# STM32WBA62 register map
File version: 1.1
CPU: CM33 r0p1, little endian, MPU, FPU, 4 interrupt priority bits
Registers are 32-bit, read-write, reset 0x0 unless marked. A register's access mark holds for its fields unless they carry their own. Offsets are from the block's base; [hi:lo] are bit positions; 'fields as' and 'values as' point back to an identical list.

## RCC — RCC address block description
Base 0x46020C00
Same registers: SEC_RCC 0x56020C00
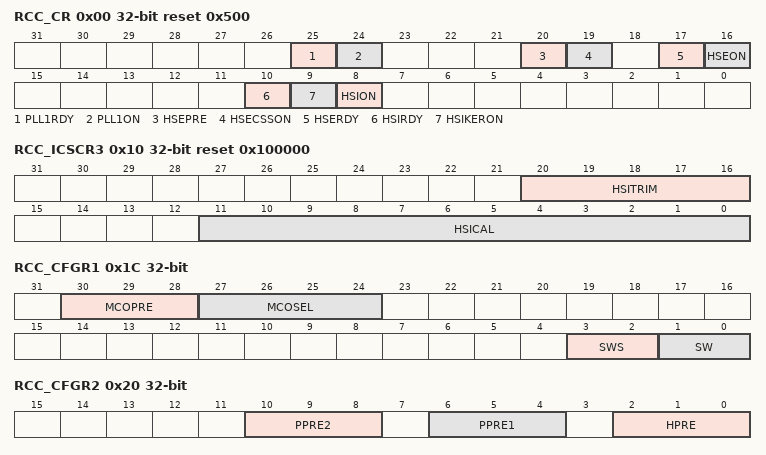
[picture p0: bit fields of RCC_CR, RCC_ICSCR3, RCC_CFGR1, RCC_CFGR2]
0x00 RCC_CR reset 0x500 — RCC clock control register
  [25] PLL1RDY ro — PLL1 clock ready flag
    0=PLL1 unlocked; 1=PLL1 locked (PLL1RDY remains set when PLL1 is selected as sysclk and PLL1 is disabled by HSECSS failure)
  [24] PLL1ON — PLL1 enable
    0=PLL1 off; 1=PLL1 on
  [20] HSEPRE — HSE32 clock for SYSCLK prescaler
    0=HSE32 not divided, SYSCLK = HSE32; 1=HSE32 divided, SYSCLK = HSE32/2
  [19] HSECSSON — HSE32 clock security system enable
    0=HSE32 clock security system off (clock detector off); 1=HSE32 clock security system on (clock detector on if the HSE32 oscillator is stable, off if not)
  [17] HSERDY ro — HSE32 clock ready flag
    0=HSE32 oscillator not ready; 1=HSE32 oscillator ready to be used by the CPU
  [16] HSEON — HSE32 clock enable
    0=HSE32 oscillator not requested by the CPU; 1=HSE32 oscillator ON
  [10] HSIRDY ro — HSI16 clock ready flag
    0=HSI16 oscillator not ready; 1=HSI16 oscillator ready
  [9] HSIKERON — HSI16 enable for some peripheral kernels
    0=No effect on HSI16 oscillator; 1=HSI16 oscillator forced on even in Stop mode
  [8] HSION — HSI16 clock enable
    0=HSI16 oscillator off; 1=HSI16 oscillator on
0x10 RCC_ICSCR3 reset 0x100000 (reset mask 0xFFFFF000) — RCC internal clock sources calibration register 3
  [20:16] HSITRIM — HSI16 clock trimming
  [11:0] HSICAL ro — HSI16 clock calibration
0x1C RCC_CFGR1 — RCC clock configuration register 1
  [30:28] MCOPRE — microcontroller clock output prescaler
    0=MCO divided by 1; 1=MCO divided by 2; 2=MCO divided by 4; 3=MCO divided by 8; 4=MCO divided by 16
  [27:24] MCOSEL — microcontroller clock output
    0=MCO output disabled, no clock on MCO; 1=sysclkpre system clock after PLL1RCLKPRE division selected; 3=HSI16 clock selected; 4=HSE32 clock selected; 5=pll1rclk clock selected; 6=LSI clock selected; 7=LSE clock selected; 8=pll1pclk clock selected; 9=pll1qclk clock selected; 10=hclk5 clock selected
  [3:2] SWS ro — system clock switch status
    0=HSI16 oscillator used as system clock; 2=HSE32 or HSE32/2, as defined by HSEPRE, used as system clock; 3=pll1rclk used as system clock
  [1:0] SW — system clock switch
    0=HSI16 selected as system clock; 2=HSE32 or HSE32/2, as defined by HSEPRE, selected as system clock; 3=pll1rclk selected as system clock
0x20 RCC_CFGR2 — RCC clock configuration register 2
  [10:8] PPRE2 — APB2 prescaler
    4=pclk2 = hclk1 divided by 2; 5=pclk2 = hclk1 divided by 4; 6=pclk2 = hclk1 divided by 8; 7=pclk2 = hclk1 divided by 16
  [6:4] PPRE1 — APB1 prescaler
    4=pclk1 = hclk1 divided by 2; 5=pclk1 = hclk1 divided by 4; 6=pclk1 = hclk1 divided by 8; 7=pclk1 = hclk1 divided by 16
  [2:0] HPRE — AHB1, AHB2 and AHB4 prescaler
    4=hclk1 = SYSCLK divided by 2; 5=hclk1 = SYSCLK divided by 4; 6=hclk1 = SYSCLK divided by 8; 7=hclk1 = SYSCLK divided by 16
0x24 RCC_CFGR3 — RCC clock configuration register 3
  [6:4] PPRE7 — APB7 prescaler
    4=hclk1 divided by 2; 5=hclk1 divided by 4; 6=hclk1 divided by 8; 7=hclk1 divided by 16
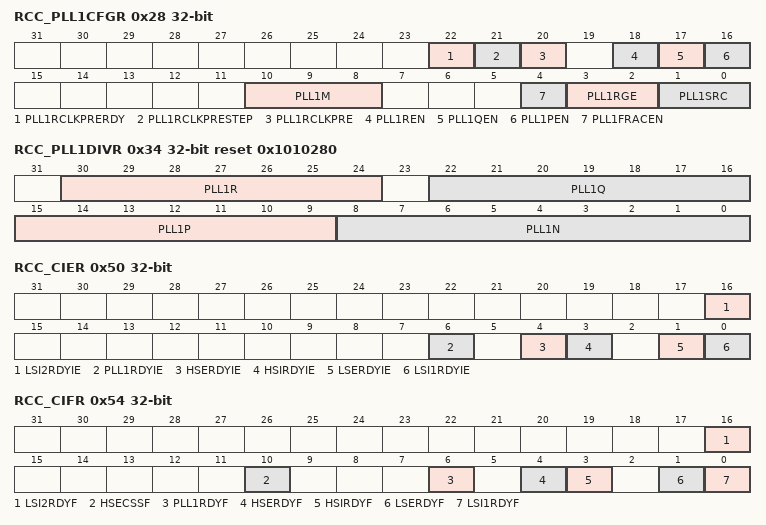
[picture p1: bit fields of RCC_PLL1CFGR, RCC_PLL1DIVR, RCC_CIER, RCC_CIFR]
0x28 RCC_PLL1CFGR — RCC PLL1 configuration register
  [22] PLL1RCLKPRERDY ro — pll1rclkpre not divided ready.
    0=pll1rclk divided; 1=pll1rclk not divided ready
  [21] PLL1RCLKPRESTEP — pll1rclk clock for SYSCLK prescaler division step selection
    0=pll1rclk 2-step division; 1=pll1rclk 3-step division
  [20] PLL1RCLKPRE — pll1rclk clock for SYSCLK prescaler division enable
    0=pll1rclk not divided, sysclkpre = pll1rclk; 1=pll1rclk divided, sysclkpre = pll1rclk divided
  [18] PLL1REN — PLL1 DIVR divider output enable
    0=pll1rclk output disabled; 1=pll1rclk output enabled
  [17] PLL1QEN — PLL1 DIVQ divider output enable
    0=pll1qclk output disabled; 1=pll1qclk output enabled
  [16] PLL1PEN — PLL1 DIVP divider output enable
    0=pll1pclk output disabled; 1=pll1pclk output enabled
  [10:8] PLL1M — Prescaler for PLL1
    0=division by 1 (bypass); 1=division by 2; 2=division by 3; 7=division by 8
  [4] PLL1FRACEN — PLL1 fractional latch enable
  [3:2] PLL1RGE — PLL1 input frequency range
    3=PLL1 input (ref_ck) clock range frequency between 8 and 16 MHz
  [1:0] PLL1SRC — PLL1 entry clock source
    0=no clock sent to PLL1; 2=HSI16 clock selected as PLL1 clock entry; 3=HSE32 clock after HSEPRE divider selected as PLL1 clock entry
0x34 RCC_PLL1DIVR reset 0x1010280 — RCC PLL1 dividers register
  [30:24] PLL1R — PLL1 DIVR division factor
    0=pll1rclk = VCO output frequency; 1=pll1rclk = VCO output frequency / 2 (default after reset); 2=pll1rclk = VCO output frequency / 3; 3=pll1rclk = VCO output frequency / 4; 127=pll1rclk = VCO output frequency / 128
  [22:16] PLL1Q — PLL1 DIVQ division factor
    0=pll1qclk = VCO output frequency; 1=pll1qclk = VCO output frequency / 2 (default after reset); 2=pll1qclk = VCO output frequency / 3; 3=pll1qclk = VCO output frequency / 4; 127=pll1qclk = VCO output frequency / 128
  [15:9] PLL1P — PLL1 DIVP division factor
    0=pll1pclk = VCO output frequency; 1=pll1pclk = VCO output frequency / 2 (default after reset); 2=pll1pclk = VCO output frequency; 3=pll1pclk = VCO output frequency / 4; 127=pll1pclk = VCO output frequency / 128
  [8:0] PLL1N — Multiplication factor for PLL1 VCO
    3=multiplication factor for PLL1 VCO = 4; 4=multiplication factor for PLL1 VCO = 5; 5=multiplication factor for PLL1 VCO = 6; 128=multiplication factor for PLL1 VCO = 129 (default after reset); 0x1FF=multiplication factor for PLL1 VCO = 512
0x38 RCC_PLL1FRACR — RCC PLL1 fractional divider register
  [15:3] PLL1FRACN — Fractional part of the multiplication factor for PLL1 VCO
0x50 RCC_CIER — RCC clock interrupt enable register
  [16] LSI2RDYIE — LSI2 ready interrupt enable
    0=LSI2 ready interrupt disabled; 1=LSI2 ready interrupt enabled
  [6] PLL1RDYIE — PLL1 ready interrupt enable
    0=PLL1 lock interrupt disabled; 1=PLL1 lock interrupt enabled
  [4] HSERDYIE — HSE32 ready interrupt enable
    0=HSE32 ready interrupt disabled; 1=HSE32 ready interrupt enabled
  [3] HSIRDYIE — HSI16 ready interrupt enable
    0=HSI16 ready interrupt disabled; 1=HSI16 ready interrupt enabled
  [1] LSERDYIE — LSE ready interrupt enable
    0=LSE ready interrupt disabled; 1=LSE ready interrupt enabled
  [0] LSI1RDYIE — LSI1 ready interrupt enable
    0=LSI1 ready interrupt disabled; 1=LSI1 ready interrupt enabled
0x54 RCC_CIFR ro — RCC clock interrupt flag register
  [16] LSI2RDYF — LSI2 ready interrupt flag
    0=no clock ready interrupt caused by the LSI2 oscillator; 1=clock ready interrupt caused by the LSI2 oscillator
  [10] HSECSSF — HSE32 clock security system interrupt flag
    0=no clock security interrupt caused by HSE32 clock failure; 1=clock security interrupt caused by HSE32 clock failure
  [6] PLL1RDYF — PLL1 ready interrupt flag
    0=no clock ready interrupt caused by PLL1 lock; 1=clock ready interrupt caused by PLL1 lock
  [4] HSERDYF — HSE32 ready interrupt flag
    0=no clock ready interrupt caused by the HSE32 oscillator; 1=clock ready interrupt caused by the HSE32 oscillator
  [3] HSIRDYF — HSI16 ready interrupt flag
    0=no clock ready interrupt caused by the HSI16 oscillator; 1=clock ready interrupt caused by the HSI16 oscillator
  [1] LSERDYF — LSE ready interrupt flag
    0=no clock ready interrupt caused by the LSE oscillator; 1=clock ready interrupt caused by the LSE oscillator
  [0] LSI1RDYF — LSI1 ready interrupt flag
    0=no clock ready interrupt caused by the LSI1 oscillator; 1=clock ready interrupt caused by the LSI1 oscillator
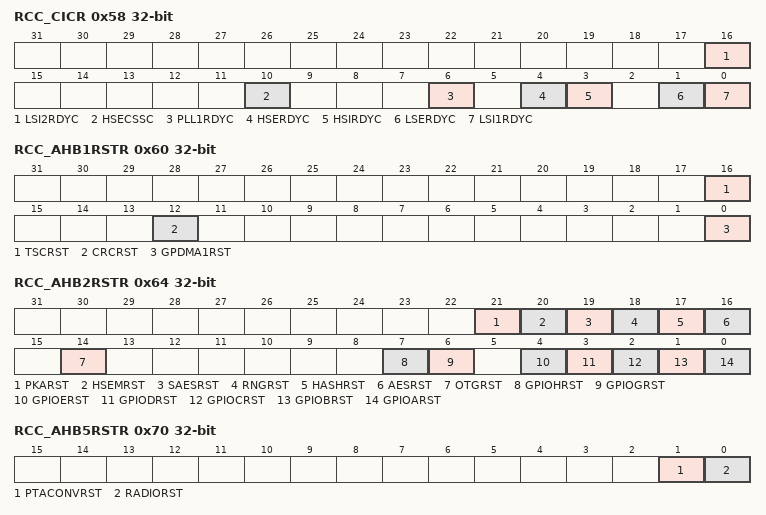
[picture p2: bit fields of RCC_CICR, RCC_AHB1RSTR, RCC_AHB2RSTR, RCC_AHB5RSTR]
0x58 RCC_CICR wo — RCC clock interrupt clear register
  [16] LSI2RDYC — LSI2 ready interrupt clear
  [10] HSECSSC — High speed external clock security system interrupt clear
  [6] PLL1RDYC — PLL1 ready interrupt clear
  [4] HSERDYC — HSE32 ready interrupt clear
  [3] HSIRDYC — HSI16 ready interrupt clear
  [1] LSERDYC — LSE ready interrupt clear
  [0] LSI1RDYC — LSI1 ready interrupt clear
0x60 RCC_AHB1RSTR — RCC AHB1 peripheral reset register
  [16] TSCRST — TSC reset
    0=No effect; 1=Reset TSC
  [12] CRCRST — CRC reset
    0=No effect; 1=Reset CRC
  [0] GPDMA1RST — GPDMA1 reset
    0=No effect; 1=Reset GPDMA1
0x64 RCC_AHB2RSTR — RCC AHB2 peripheral reset register
  [21] PKARST — PKA reset
    0=No effect; 1=Reset PKA
  [20] HSEMRST — HSEM reset
    0=No effect; 1=Reset HSEM
  [19] SAESRST — SAES hardware accelerator reset
    0=No effect; 1=Reset SAES
  [18] RNGRST — Random number generator reset
    0=No effect; 1=Reset RNG
  [17] HASHRST — Hash reset
    0=No effect; 1=Reset HASH
  [16] AESRST — AES hardware accelerator reset
    0=No effect; 1=Reset AES
  [14] OTGRST — USB OTG_HS reset
    0=No effect; 1=Reset USB OTG_HS and USB OTG_HS PHY
  [7] GPIOHRST — IO port H reset
    0=No effect; 1=Reset IO port H
  [6] GPIOGRST — IO port G reset
    0=No effect; 1=Reset IO port G
  [4] GPIOERST — IO port E reset
    0=No effect; 1=Reset IO port E
  [3] GPIODRST — IO port D reset
    0=No effect; 1=Reset IO port D
  [2] GPIOCRST — IO port C reset
    0=No effect; 1=Reset IO port C
  [1] GPIOBRST — IO port B reset
    0=No effect; 1=Reset IO port B
  [0] GPIOARST — IO port A reset
    0=No effect; 1=Reset IO port A
0x6C RCC_AHB4RSTR — RCC AHB4 peripheral reset register
  [5] ADC4RST — ADC4 reset
    0=No effect; 1=Reset ADC4 interface
0x70 RCC_AHB5RSTR — RCC AHB5 peripheral reset register
  [1] PTACONVRST — PTACONV reset
    0=No effect; 1=Reset PTACONV
  [0] RADIORST — 2.
    0=No effect; 1=Reset 2
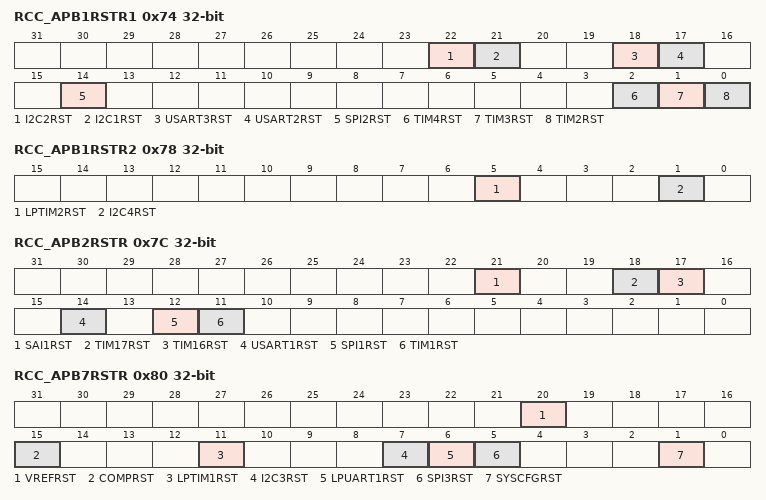
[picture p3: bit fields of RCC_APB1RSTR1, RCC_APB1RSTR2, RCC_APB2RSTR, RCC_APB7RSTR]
0x74 RCC_APB1RSTR1 — RCC APB1 peripheral reset register 1
  [22] I2C2RST — I2C2 reset
    0=No effect; 1=Reset I2C2
  [21] I2C1RST — I2C1 reset
    0=No effect; 1=Reset I2C1
  [18] USART3RST — USART3 reset
    0=No effect; 1=Reset USART3
  [17] USART2RST — USART2 reset
    0=No effect; 1=Reset USART2
  [14] SPI2RST — SPI2 reset
    0=No effect; 1=Reset SPI2
  [2] TIM4RST — TIM4 reset
    0=No effect; 1=Reset TIM4
  [1] TIM3RST — TIM3 reset
    0=No effect; 1=Reset TIM3
  [0] TIM2RST — TIM2 reset
    0=No effect; 1=Reset TIM2
0x78 RCC_APB1RSTR2 — RCC APB1 peripheral reset register 2
  [5] LPTIM2RST — LPTIM2 reset
    0=No effect; 1=Reset LPTIM2
  [1] I2C4RST — I2C4 reset
    0=No effect; 1=Reset I2C4
0x7C RCC_APB2RSTR — RCC APB2 peripheral reset register
  [21] SAI1RST — SAI1 reset
    0=No effect; 1=Reset SAI1
  [18] TIM17RST — TIM17 reset
    0=No effect; 1=Reset TIM17
  [17] TIM16RST — TIM16 reset
    0=No effect; 1=Reset TIM16
  [14] USART1RST — USART1 reset
    0=No effect; 1=Reset USART1
  [12] SPI1RST — SPI1 reset
    0=No effect; 1=Reset SPI1
  [11] TIM1RST — TIM1 reset
    0=No effect; 1=Reset TIM1
0x80 RCC_APB7RSTR — RCC APB7 peripheral reset register
  [20] VREFRST — VREFBUF reset
    0=No effect; 1=Reset VREFBUF
  [15] COMPRST — COMP reset
    0=No effect; 1=Reset COMP
  [11] LPTIM1RST — LPTIM1 reset
    0=No effect; 1=Reset LPTIM1
  [7] I2C3RST — I2C3 reset
    0=No effect; 1=Reset I2C3
  [6] LPUART1RST — LPUART1 reset
    0=No effect; 1=Reset LPUART1
  [5] SPI3RST — SPI3 reset
    0=No effect; 1=Reset SPI3
  [1] SYSCFGRST — SYSCFG reset
    0=No effect; 1=Reset SYSCFG
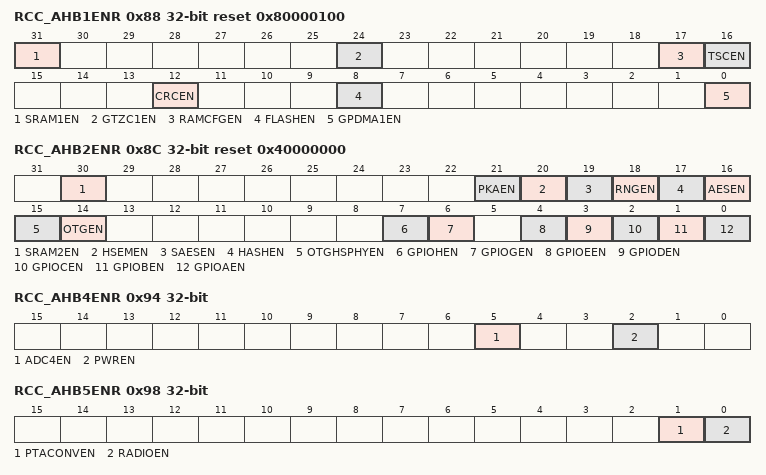
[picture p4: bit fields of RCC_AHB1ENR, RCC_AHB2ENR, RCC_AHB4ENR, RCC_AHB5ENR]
0x88 RCC_AHB1ENR reset 0x80000100 — RCC AHB1 peripheral clock enable register
  [31] SRAM1EN — SRAM1 bus clock enable
    0=SRAM1 bus clock disabled; 1=SRAM1 bus clock enabled
  [24] GTZC1EN — GTZC1 bus clock enable
    0=GTZC1 bus clock disabled; 1=GTZC1 bus clock enabled
  [17] RAMCFGEN — RAMCFG bus clock enable
    0=RAMCFG bus clock disabled; 1=RAMCFG bus clock enabled
  [16] TSCEN — Touch sensing controller bus clock enable
    0=TSC bus clock disabled; 1=TSC bus clock enabled
  [12] CRCEN — CRC bus clock enable
    0=CRC bus clock disabled; 1=CRC bus clock enabled
  [8] FLASHEN — FLASH bus clock enable
    0=FLASH bus clock disabled; 1=FLASH bus clock enabled
  [0] GPDMA1EN — GPDMA1 bus clock enable
    0=GPDMA1 bus clock disabled; 1=GPDMA1 bus clock enabled
0x8C RCC_AHB2ENR reset 0x40000000 — RCC AHB2 peripheral clock enable register
  [30] SRAM2EN — SRAM2 bus clock enable
    0=SRAM2 bus clock disabled; 1=SRAM2 bus clock enabled
  [21] PKAEN — PKA bus clock enable
    0=PKA bus clock disabled; 1=PKA bus clock enabled
  [20] HSEMEN — HSEM bus clock enable
    0=HSEM bus clock disabled; 1=HSEM bus clock enabled
  [19] SAESEN — SAES bus clock enable
    0=SAES bus clock disabled; 1=SAES bus clock enabled
  [18] RNGEN — RNG bus and kernel clocks enable
    0=RNG bus and kernel clocks disabled; 1=RNG bus and kernel clocks enabled
  [17] HASHEN — HASH bus clock enable
    0=HASH bus clock disabled; 1=HASH bus clock enabled
  [16] AESEN — AES bus clock enable
    0=AES bus clock disabled; 1=AES bus clock enabled
  [15] OTGHSPHYEN — USB OTG_HS PHY kernel clock enable
    0=USB OTG_HS PHY kernel clock disabled; 1=USB OTG_HS PHY kernel clock enabled
  [14] OTGEN — USB OTG_HS bus and kernel clock enable
    0=USB OTG_HS bus and kernel clock disabled; 1=USB OTG_HS bus and kernel clock enabled
  [7] GPIOHEN — IO port H bus clock enable
    0=IO port H bus clock disabled; 1=IO port H bus clock enabled
  [6] GPIOGEN — IO port G bus clock enable
    0=IO port G bus clock disabled; 1=IO port G bus clock enabled
  [4] GPIOEEN — IO port E bus clock enable
    0=IO port E bus clock disabled; 1=IO port E bus clock enabled
  [3] GPIODEN — IO port D bus clock enable
    0=IO port D bus clock disabled; 1=IO port D bus clock enabled
  [2] GPIOCEN — IO port C bus clock enable
    0=IO port C bus clock disabled; 1=IO port C bus clock enabled
  [1] GPIOBEN — IO port B bus clock enable
    0=IO port B bus clock disabled; 1=IO port B bus clock enabled
  [0] GPIOAEN — IO port A bus clock enable
    0=IO port A bus clock disabled; 1=IO port A bus clock enabled
0x94 RCC_AHB4ENR — RCC AHB4 peripheral clock enable register
  [5] ADC4EN — ADC4 bus and kernel clocks enable
    0=ADC4 bus and kernel clocks disabled; 1=ADC4 bus and kernel clocks enabled
  [2] PWREN — PWR bus clock enable
    0=PWR bus clock disabled; 1=PWR bus clock enabled
0x98 RCC_AHB5ENR — RCC AHB5 peripheral clock enable register
  [1] PTACONVEN — PTACONV bus clock enable
    0=PTACONV bus clock disabled; 1=PTACONV bus clock enabled
  [0] RADIOEN — 2.
    0=2; 1=2
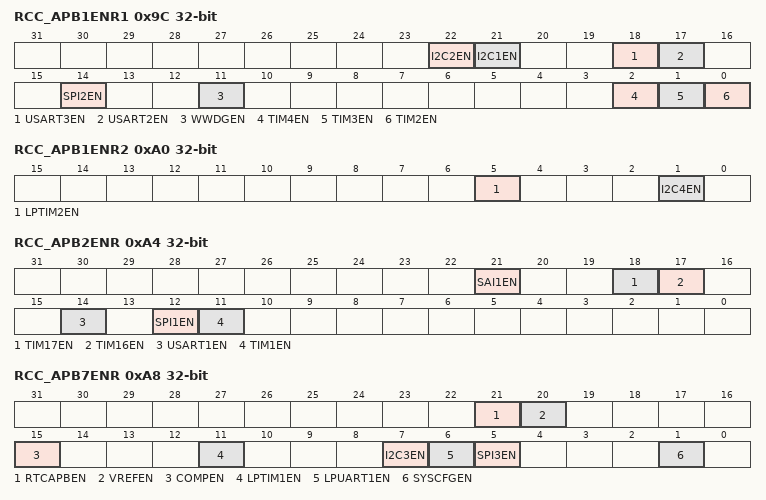
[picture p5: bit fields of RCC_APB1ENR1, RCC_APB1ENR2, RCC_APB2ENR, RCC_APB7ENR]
0x9C RCC_APB1ENR1 — RCC APB1 peripheral clock enable register 1
  [22] I2C2EN — I2C2 bus and kernel clocks enable
    0=I2C2 bus and kernel clocks disabled; 1=I2C2 bus and kernel clocks enabled
  [21] I2C1EN — I2C1 bus and kernel clocks enable
    0=I2C1 bus and kernel clocks disabled; 1=I2C1 bus and kernel clocks enabled
  [18] USART3EN — USART3 bus and kernel clocks enable
    0=USART3 bus and kernel clocks disabled; 1=USART3 bus and kernel clocks enabled
  [17] USART2EN — USART2 bus and kernel clocks enable
    0=USART2 bus and kernel clocks disabled; 1=USART2 bus and kernel clocks enabled
  [14] SPI2EN — SPI2 bus and kernel clocks enable
    0=SPI2 bus and kernel clocks disabled; 1=SPI2 bus and kernel clocks enabled
  [11] WWDGEN — WWDG bus clock enable
    0=WWDG bus clock disabled; 1=WWDG bus clock enabled
  [2] TIM4EN — TIM4 bus and kernel clocks enable
    0=TIM4 bus and kernel clocks disabled; 1=TIM4 bus and kernel clocks enabled
  [1] TIM3EN — TIM3 bus and kernel clocks enable
    0=TIM3 bus and kernel clocks disabled; 1=TIM3 bus and kernel clocks enabled
  [0] TIM2EN — TIM2 bus and kernel clocks enable
    0=TIM2 bus and kernel clocks disabled; 1=TIM2 bus and kernel clocks enabled
0xA0 RCC_APB1ENR2 — RCC APB1 peripheral clock enable register 2
  [5] LPTIM2EN — LPTIM2 bus and kernel clocks enable
    0=LPTIM2 bus and kernel clocks disabled; 1=LPTIM2 bus and kernel clocks enabled
  [1] I2C4EN — I2C4 bus and kernel clocks enable
    0=I2C4 bus and kernel clocks disabled; 1=I2C4 bus and kernel clocks enabled
0xA4 RCC_APB2ENR — RCC APB2 peripheral clock enable register
  [21] SAI1EN — SAI1 bus and kernel clocks enable
    0=SAI1 bus and kernel clocks disabled; 1=SAI1 bus and kernel clocks enabled
  [18] TIM17EN — TIM17 bus and kernel clocks enable
    0=TIM17 bus and kernel clocks disabled; 1=TIM17 bus and kernel clocks enabled
  [17] TIM16EN — TIM16 bus and kernel clocks enable
    0=TIM16 bus and kernel clocks disabled; 1=TIM16 bus and kernel clocks enabled
  [14] USART1EN — USART1bus and kernel clocks enable
    0=USART1 bus and kernel clocks disabled; 1=USART1 bus and kernel clocks enabled
  [12] SPI1EN — SPI1 bus and kernel clocks enable
    0=SPI1 bus and kernel clocks disabled; 1=SPI1 bus and kernel clocks enabled
  [11] TIM1EN — TIM1 bus and kernel clocks enable
    0=TIM1 bus and kernel clocks disabled; 1=TIM1 bus and kernel clocks enabled
0xA8 RCC_APB7ENR — RCC APB7 peripheral clock enable register
  [21] RTCAPBEN — RTC and TAMP bus clock enable
    0=RTC bus clock disabled; 1=RTC bus clock enabled
  [20] VREFEN — VREFBUF bus clock enable
    0=VREFBUF bus clock disabled; 1=VREFBUS bus clock enabled
  [15] COMPEN — COMP bus clock enable
    0=COMP bus clock disabled; 1=COMP bus clock enabled
  [11] LPTIM1EN — LPTIM1 bus and kernel clocks enable
    0=LPTIM1 bus and kernel clocks disabled; 1=LPTIM1 bus and kernel clocks enabled
  [7] I2C3EN — I2C3 bus and kernel clocks enable
    0=I2C3 bus and kernel clocks disabled; 1=I2C3 bus and kernel clocks enabled
  [6] LPUART1EN — LPUART1 bus and kernel clocks enable
    0=LPUART1 bus and kernel clocks disabled; 1=LPUART1 bus and kernel clocks enabled
  [5] SPI3EN — SPI3 bus and kernel clocks enable
    0=SPI3 bus and kernel clocks disabled; 1=SPI3 bus and kernel clocks enabled
  [1] SYSCFGEN — SYSCFG bus clock enable
    0=SYSCFG bus clock disabled; 1=SYSCFG bus clock enabled
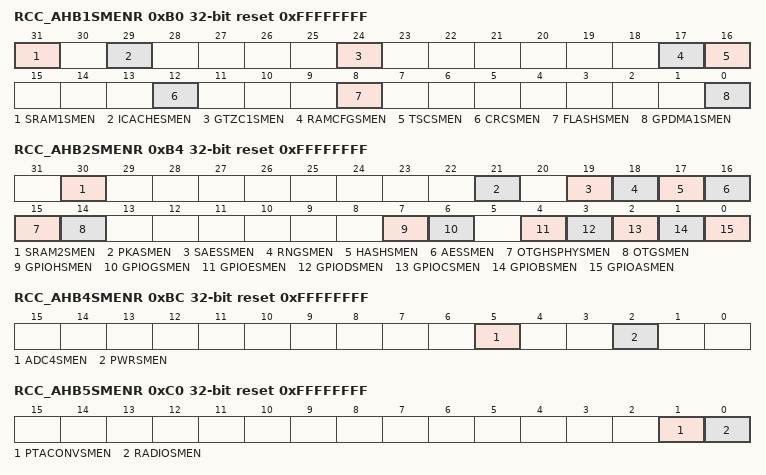
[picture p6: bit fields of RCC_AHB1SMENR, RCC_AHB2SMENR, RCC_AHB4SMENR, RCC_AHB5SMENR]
0xB0 RCC_AHB1SMENR reset 0xFFFFFFFF — RCC AHB1 peripheral clocks enable in Sleep and Stop modes register
  [31] SRAM1SMEN — SRAM1 bus clock enable during Sleep and Stop modes
    0=SRAM1 bus clock disabled by the clock gating during Sleep and Stop modes; 1=SRAM1 bus clock enabled by the clock gating during Sleep and Stop modes
  [29] ICACHESMEN — ICACHE bus clock enable during Sleep and Stop modes
    0=ICACHE bus clock disabled by the clock gating during Sleep and Stop modes; 1=ICACHE bus clock enabled by the clock gating during Sleep and Stop modes
  [24] GTZC1SMEN — GTZC1 bus clock enable during Sleep and Stop modes
    0=GTZC1 bus clock disabled by the clock gating during Sleep and Stop modes; 1=GTZC1 bus clock enabled by the clock gating during Sleep and Stop modes
  [17] RAMCFGSMEN — RAMCFG bus clock enable during Sleep and Stop modes
    0=RAMCFG bus clock disabled by the clock gating during Sleep and Stop modes; 1=RAMCFG bus clock enabled by the clock gating during Sleep and Stop modes
  [16] TSCSMEN — TSC bus clock enable during Sleep and Stop modes
    0=TSC bus clock disabled by the clock gating during Sleep and Stop modes; 1=TSC bus clock enabled by the clock gating during Sleep and Stop modes
  [12] CRCSMEN — CRC bus clock enable during Sleep and Stop modes
    0=CRC bus clock disabled by the clock gating during Sleep and Stop modes; 1=CRC bus clock enabled by the clock gating during Sleep and Stop modes
  [8] FLASHSMEN — FLASH bus clock enable during Sleep and Stop modes
    0=FLASH bus clock disabled by the clock gating during Sleep and Stop modes; 1=FLASH bus clock enabled by the clock gating during Sleep and Stop modes
  [0] GPDMA1SMEN — GPDMA1 bus clock enable during Sleep and Stop modes
    0=GPDMA1 bus clock disabled by the clock gating during Sleep and Stop modes; 1=GPDMA1 bus clock enabled by the clock gating during Sleep and Stop modes
0xB4 RCC_AHB2SMENR reset 0xFFFFFFFF — RCC AHB2 peripheral clocks enable in Sleep and Stop modes register
  [30] SRAM2SMEN — SRAM2 bus clock enable during Sleep and Stop modes
    0=SRAM2 bus clock disabled by the clock gating during Sleep and Stop modes; 1=SRAM2 bus clock enabled by the clock gating during Sleep and Stop modes
  [21] PKASMEN — PKA bus clock enable during Sleep and Stop modes
    0=PKA bus clock disabled by the clock gating during Sleep and Stop modes; 1=PKA bus clock enabled by the clock gating during Sleep and Stop modes
  [19] SAESSMEN — SAES accelerator bus clock enable during Sleep and Stop modes
    0=SAES bus clock disabled by the clock gating during Sleep and Stop modes; 1=SAES bus clock enabled by the clock gating during Sleep and Stop modes
  [18] RNGSMEN — Random number generator (RNG) bus and kernel clocks enable during Sleep and Stop modes
    0=RNG bus and kernel clocks disabled by the clock gating during Sleep and Stop modes; 1=RNG bus and kernel clocks enabled by the clock gating during Sleep and Stop modes
  [17] HASHSMEN — HASH bus clock enable during Sleep and Stop modes
    0=HASH bus clock disabled by the clock gating during Sleep and Stop modes; 1=HASH bus clock enabled by the clock gating during Sleep and Stop modes
  [16] AESSMEN — AES bus clock enable during Sleep and Stop modes
    0=AES bus clock disabled by the clock gating during Sleep and Stop modes; 1=AES bus clock enabled by the clock gating during Sleep and Stop modes
  [15] OTGHSPHYSMEN — USB OTG_HS PHY kernel clock enable during Sleep and Stop modes
    0=USB OTG_HS PHY kernel clock disabled by the clock gating during Sleep and Stop modes; 1=USB OTG_HS PHY kernel clock enabled by the clock gating during Sleep and Stop modes
  [14] OTGSMEN — USB OTG_HS bus and kernel clocks enable during Sleep and Stop modes
    0=USB OTG_HS bus and kernel clocks disabled by the clock gating during Sleep and Stop modes; 1=USB OTG_HS bus and kernel clocks enabled by the clock gating during Sleep and Stop modes
  [7] GPIOHSMEN — IO port H bus clock enable during Sleep and Stop modes
    0=IO port H bus clock disabled by the clock gating during Sleep and Stop modes; 1=IO port H bus clock enabled by the clock gating during Sleep and Stop modes
  [6] GPIOGSMEN — IO port G bus clock enable during Sleep and Stop modes
    0=IO port G bus clock disabled by the clock gating during Sleep and Stop modes; 1=IO port G bus clock enabled by the clock gating during Sleep and Stop modes
  [4] GPIOESMEN — IO port E bus clock enable during Sleep and Stop modes
    0=IO port E bus clock disabled by the clock gating during Sleep and Stop modes; 1=IO port E bus clock enabled by the clock gating during Sleep and Stop modes
  [3] GPIODSMEN — IO port D bus clock enable during Sleep and Stop modes
    0=IO port D bus clock disabled by the clock gating during Sleep and Stop modes; 1=IO port D bus clock enabled by the clock gating during Sleep and Stop modes
  [2] GPIOCSMEN — IO port C bus clock enable during Sleep and Stop modes
    0=IO port C bus clock disabled by the clock gating during Sleep and Stop modes; 1=IO port C bus clock enabled by the clock gating during Sleep and Stop modes
  [1] GPIOBSMEN — IO port B bus clock enable during Sleep and Stop modes
    0=IO port B bus clock disabled by the clock gating during Sleep and Stop modes; 1=IO port B bus clock enabled by the clock gating during Sleep and Stop modes
  [0] GPIOASMEN — IO port A bus clock enable during Sleep and Stop modes
    0=IO port A bus clock disabled by the clock gating during Sleep and Stop modes; 1=IO port A bus clock enabled by the clock gating during Sleep and Stop modes
0xBC RCC_AHB4SMENR reset 0xFFFFFFFF — RCC AHB4 peripheral clocks enable in Sleep and Stop modes register
  [5] ADC4SMEN — ADC4 bus and kernel clocks enable during Sleep and Stop modes
    0=ADC4 bus and kernel clocks disabled by the clock gating during Sleep and Stop modes; 1=ADC4 bus and kernel clocks enabled by the clock gating during Sleep and Stop modes
  [2] PWRSMEN — PWR bus clock enable during Sleep and Stop modes
    0=PWR bus clock disabled by the clock gating during Sleep and Stop modes; 1=PWR bus clock enabled by the clock gating during Sleep and Stop modes
0xC0 RCC_AHB5SMENR reset 0xFFFFFFFF — RCC AHB5 peripheral clocks enable in Sleep and Stop modes register
  [1] PTACONVSMEN — PTACONV bus clock enable during Sleep and Stop modes
    0=PTACONV bus clock disabled by the clock gating during Sleep and Stop modes; 1=PTACONV bus clock enabled by the clock gating during Sleep and Stop modes
  [0] RADIOSMEN — 2.
    0=2; 1=2
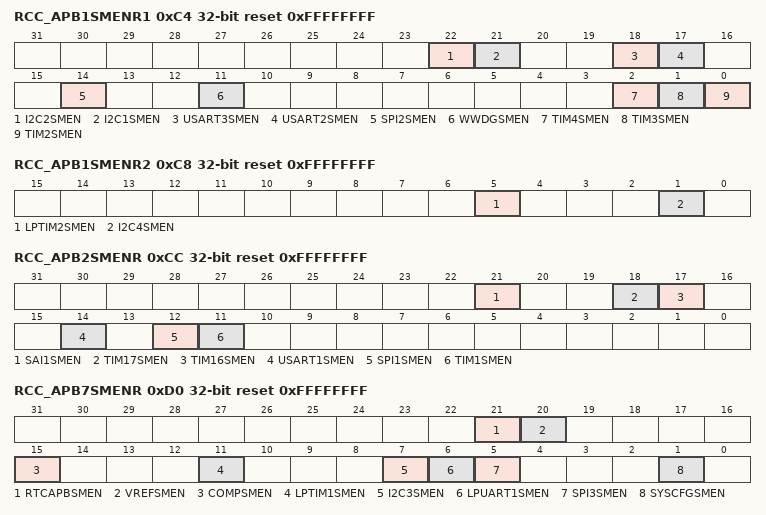
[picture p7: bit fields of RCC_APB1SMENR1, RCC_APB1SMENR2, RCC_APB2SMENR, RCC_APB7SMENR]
0xC4 RCC_APB1SMENR1 reset 0xFFFFFFFF — RCC APB1 peripheral clocks enable in Sleep and Stop modes register 1
  [22] I2C2SMEN — I2C2 bus and kernel clocks enable during Sleep and Stop modes
    0=I2C2 bus and kernel clocks disabled by the clock gating during Sleep and Stop modes; 1=I2C2 bus and kernel clocks enabled by the clock gating during Sleep and Stop modes
  [21] I2C1SMEN — I2C1 bus and kernel clocks enable during Sleep and Stop modes
    0=I2C1 bus and kernel clocks disabled by the clock gating during Sleep and Stop modes; 1=I2C1 bus and kernel clocks enabled by the clock gating during Sleep and Stop modes
  [18] USART3SMEN — USART3 bus and kernel clocks enable during Sleep and Stop modes
    0=USART3 bus and kernel clocks disabled by the clock gating during Sleep and Stop modes; 1=USART3 bus and kernel clocks enabled by the clock gating during Sleep and Stop modes
  [17] USART2SMEN — USART2 bus and kernel clocks enable during Sleep and Stop modes
    0=USART2 bus and kernel clocks disabled by the clock gating during Sleep and Stop modes; 1=USART2 bus and kernel clocks enabled by the clock gating during Sleep and Stop modes
  [14] SPI2SMEN — SPI2 bus and kernel clocks enable during Sleep and Stop modes
    0=SPI2 bus and kernel clocks disabled by the clock gating during Sleep and Stop modes; 1=SPI2 bus and kernel clocks enabled by the clock gating during Sleep and Stop modes
  [11] WWDGSMEN — Window watchdog bus clock enable during Sleep and Stop modes
    0=WWDG bus clock disabled by the clock gating during Sleep mode; 1=WWDG bus clock enabled by the clock gating during Sleep mode
  [2] TIM4SMEN — TIM4 bus and kernel clocks enable during Sleep and Stop modes
    0=TIM4 bus and kernel clocks disabled by the clock gating during Sleep and Stop modes; 1=TIM4 bus and kernel clocks enabled by the clock gating during Sleep and Stop modes
  [1] TIM3SMEN — TIM3 bus and kernel clocks enable during Sleep and Stop modes
    0=TIM3 bus and kernel clocks disabled by the clock gating during Sleep and Stop modes; 1=TIM3 bus and kernel clocks enabled by the clock gating during Sleep and Stop modes
  [0] TIM2SMEN — TIM2 bus and kernel clocks enable during Sleep and Stop modes
    0=TIM2 bus and kernel clocks disabled by the clock gating during Sleep and Stop modes; 1=TIM2 bus and kernel clocks enabled by the clock gating during Sleep and Stop modes
0xC8 RCC_APB1SMENR2 reset 0xFFFFFFFF — RCC APB1 peripheral clocks enable in Sleep and Stop modes register 2
  [5] LPTIM2SMEN — LPTIM2 bus and kernel clocks enable during Sleep and Stop modes
    0=LPTIM2 bus and kernel clocks disabled by the clock gating during Sleep and Stop modes; 1=LPTIM2 bus and kernel clocks enabled by the clock gating during Sleep and Stop modes
  [1] I2C4SMEN — I2C4 bus and kernel clocks enable during Sleep and Stop modes
    0=I2C4 bus and kernel clocks disabled by the clock gating during Sleep and Stop modes; 1=I2C4 bus and kernel clocks enabled by the clock gating during Sleep and Stop modes
0xCC RCC_APB2SMENR reset 0xFFFFFFFF — RCC APB2 peripheral clocks enable in Sleep and Stop modes register
  [21] SAI1SMEN — SAI1 bus and kernel clocks enable during Sleep and Stop modes
    0=SAI1 bus and kernel clocks disabled by the clock gating during Sleep and Stop modes; 1=SAI1 bus and kernel clocks enabled by the clock gating during Sleep and Stop modes
  [18] TIM17SMEN — TIM17 bus and kernel clocks enable during Sleep and Stop modes
    0=TIM17 bus and kernel clocks disabled by the clock gating during Sleep and Stop modes; 1=TIM17 bus and kernel clocks enabled by the clock gating during Sleep and Stop modes
  [17] TIM16SMEN — TIM16 bus and kernel clocks enable during Sleep and Stop modes
    0=TIM16 bus and kernel clocks disabled by the clock gating during Sleep and Stop modes; 1=TIM16 bus and kernel clocks enabled by the clock gating during Sleep and Stop modes
  [14] USART1SMEN — USART1 bus and kernel clocks enable during Sleep and Stop modes
    0=USART1 bus and kernel clocks disabled by the clock gating during Sleep and Stop modes; 1=USART1 bus and kernel clocks enabled by the clock gating during Sleep and Stop modes
  [12] SPI1SMEN — SPI1 bus and kernel clocks enable during Sleep and Stop modes
    0=SPI1 bus and kernel clocks disabled by the clock gating during Sleep and Stop modes; 1=SPI1 bus and kernel clocks enabled by the clock gating during Sleep and Stop modes
  [11] TIM1SMEN — TIM1 bus and kernel clocks enable during Sleep and Stop modes
    0=TIM1 bus and kernel clocks disabled by the clock gating during Sleep and Stop modes; 1=TIM1 bus and kernel clocks enabled by the clock gating during Sleep and Stop modes
0xD0 RCC_APB7SMENR reset 0xFFFFFFFF — RCC APB7 peripheral clock enable in Sleep and Stop modes register
  [21] RTCAPBSMEN — RTC and TAMP APB clock enable during Sleep and Stop modes
    0=RTC and TAMP APB clock disabled by the clock gating during Sleep and Stop modes; 1=RTC and TAMP APB clock enabled by the clock gating during Sleep and Stop modes
  [20] VREFSMEN — VREFBUF bus clock enable during Sleep and Stop modes
    0=VREFBUF bus clock disabled by the clock gating during Sleep and Stop modes; 1=VREFBUF bus clock enabled by the clock gating during Sleep and Stop modes
  [15] COMPSMEN — COMP bus clock enable during Sleep and Stop modes
    0=COMP bus clock disabled by the clock gating during Sleep and Stop modes; 1=COMP bus clock enabled by the clock gating during Sleep and Stop modes
  [11] LPTIM1SMEN — LPTIM1 bus and kernel clocks enable during Sleep and Stop modes
    0=LPTIM1 bus and kernel clocks disabled by the clock gating during Sleep and Stop modes; 1=LPTIM1 bus and kernel clocks enabled by the clock gating during Sleep and Stop modes
  [7] I2C3SMEN — I2C3 bus and kernel clocks enable during Sleep and Stop modes
    0=I2C3 bus and kernel clocks disabled by the clock gating during Sleep and Stop modes; 1=I2C3 bus and kernel clocks enabled by the clock gating during Sleep and Stop modes
  [6] LPUART1SMEN — LPUART1 bus and kernel clocks enable during Sleep and Stop modes
    0=LPUART1 bus and kernel clocks disabled by the clock gating during Sleep and Stop modes; 1=LPUART1 bus and kernel clocks enabled by the clock gating during Sleep and Stop modes
  [5] SPI3SMEN — SPI3 bus and kernel clocks enable during Sleep and Stop modes
    0=SPI3 bus and kernel clocks disabled by the clock gating during Sleep and Stop modes; 1=SPI3 bus and kernel clocks enabled by the clock gating during Sleep and Stop modes
  [1] SYSCFGSMEN — SYSCFG bus clock enable during Sleep and Stop modes
    0=SYSCFG bus clock disabled by the clock gating during Sleep and Stop modes; 1=SYSCFG bus clock enabled by the clock gating during Sleep and Stop modes
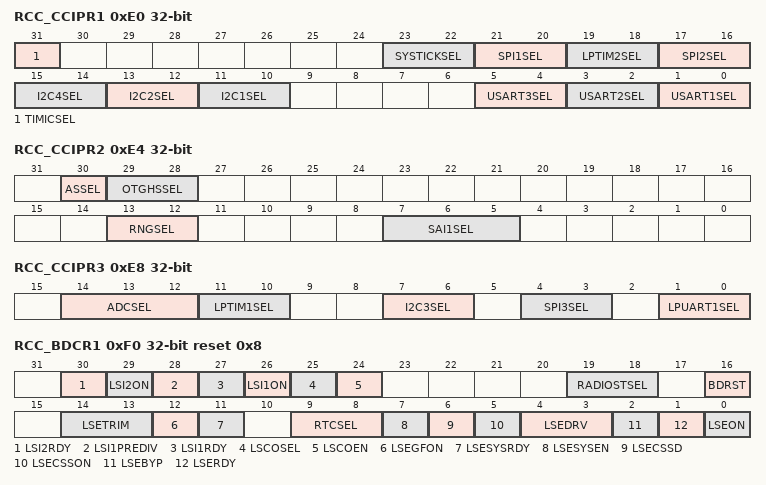
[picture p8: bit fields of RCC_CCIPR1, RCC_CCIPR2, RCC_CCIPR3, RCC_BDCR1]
0xE0 RCC_CCIPR1 — RCC peripherals independent clock configuration register 1
  [31] TIMICSEL — Clocks sources for TIM16,TIM17 and LPTIM2 internal input capture
    0=HSI16 divider disabled; 1=HSI16/256 generated and can be selected by TIM16, TIM17 and LPTIM2 as internal input capture
  [23:22] SYSTICKSEL — SysTick clock source selection
    0=hclk1 divided by 8 selected; 1=LSI selected; 2=LSE selected; 3=HSI16 divided by 4 selected
  [21:20] SPI1SEL — SPI1 kernel clock source selection
    0=pclk2 selected; 1=SYSCLK selected; 2=HSI16 selected
  [19:18] LPTIM2SEL — Low-power timer 2 kernel clock source selection
    0=pclk1 selected; 1=LSI selected; 2=HSI16 selected; 3=LSE selected
  [17:16] SPI2SEL — SPI2 kernel clock source selection
    0=pclk1 selected; 1=SYSCLK selected; 2=HSI16 selected
  [15:14] I2C4SEL — I2C4 kernel clock source selection
    0=pclk1 selected; 1=SYSCLK selected; 2=HSI16 selected
  [13:12] I2C2SEL — I2C2 kernel clock source selection
    0=pclk1 selected; 1=SYSCLK selected; 2=HSI16 selected
  [11:10] I2C1SEL — I2C1 kernel clock source selection
    0=pclk1 selected; 1=SYSCLK selected; 2=HSI16 selected
  [5:4] USART3SEL — USART3 kernel clock source selection
    0=pclk1 selected; 1=SYSCLK selected; 2=HSI16 selected; 3=LSE selected
  [3:2] USART2SEL — USART2 kernel clock source selection
    values as USART3SEL
  [1:0] USART1SEL — USART1 kernel clock source selection
    0=pclk2 selected; 1=SYSCLK selected; 2=HSI16 selected; 3=LSE selected
0xE4 RCC_CCIPR2 — RCC peripherals independent clock configuration register 2
  [30] ASSEL — RCC audio synchronization kernel clock source selection
    0=pll1pclk selected; 1=pll1qclk selected
  [29:28] OTGHSSEL — USB OTG_HS PHY kernel clock source selection
    0=HSE32 selected; 1=pll1pclk selected,; 2=HSE32 divided by 2 selected; 3=pll1pclk divided by 2 selected
  [13:12] RNGSEL — RNGSEL kernel clock source selection
    0=LSE selected; 1=LSI selected; 2=HSI16 selected; 3=pll1qclk divide by 2 selected
  [7:5] SAI1SEL — SAI1 kernel clock source selection
    0=pll1pclk selected; 1=pll1qclk selected; 2=SYSCLK selected; 3=input pin AUDIOCLK selected; 4=HSI16 clock selected
0xE8 RCC_CCIPR3 — RCC peripherals independent clock configuration register 3
  [14:12] ADCSEL — ADC4 kernel clock source selection
    0=hclk1 clock selected; 1=SYSCLK selected; 2=pll1pclk selected; 3=HSE32 clock selected; 4=HSI16 clock selected
  [11:10] LPTIM1SEL — LPTIM1 kernel clock source selection
    0=pclk7 selected; 1=LSI selected; 2=HSI16 selected; 3=LSE selected
  [7:6] I2C3SEL — I2C3 kernel clock source selection
    0=pclk7 selected; 1=SYSCLK selected; 2=HSI16 selected
  [4:3] SPI3SEL — SPI3 kernel clock source selection
    0=pclk7 selected; 1=SYSCLK selected; 2=HSI16 selected
  [1:0] LPUART1SEL — LPUART1 kernel clock source selection
    0=pclk7 selected; 1=SYSCLK selected; 2=HSI16 selected; 3=LSE selected
0xF0 RCC_BDCR1 reset 0x8 (reset mask 0xFFFF0FFF) — RCC Backup domain control register
  [30] LSI2RDY ro — LSI2 oscillator ready
    0=LSI2 oscillator not ready; 1=LSI2 oscillator ready
  [29] LSI2ON — LSI2 oscillator enable
    0=LSI2 oscillator off; 1=LSI2 oscillator on
  [28] LSI1PREDIV — LSI1 Low-speed clock divider configuration
    0=LSI1 not divided; 1=LSI1 divided by 128
  [27] LSI1RDY ro — LSI1 oscillator ready
    0=LSI1 oscillator not ready; 1=LSI1 oscillator ready
  [26] LSI1ON — LSI1 oscillator enable
    0=LSI1 oscillator off; 1=LSI1 oscillator on
  [25] LSCOSEL — Low-speed clock output selection
    0=LSI clock selected; 1=LSE clock selected
  [24] LSCOEN — Low-speed clock output (LSCO) enable
    0=LSCO disabled; 1=LSCO enabled
  [19:18] RADIOSTSEL — 2.
    0=no clock selected, 2; 1=LSE oscillator clock selected; 2=LSI oscillator clock selected; 3=HSE32 oscillator clock divided by 1000 selected
  [16] BDRST — Backup domain software reset
    0=Reset not activated; 1=Reset the entire Backup domain when the protection is disabled
  [14:13] LSETRIM — LSE trimming
    0=current source resistance 5/4 x R; 1=current source resistance R; 2=current source resistance 3/4 x R; 3=current source resistance 2/3 x R
  [12] LSEGFON — LSE clock glitch filter enable
    0=LSE glitch filter disabled; 1=LSE glitch filter enabled
  [11] LSESYSRDY ro — LSE system clock (LSESYS) ready
    0=LSESYS clock not ready; 1=LSESYS clock ready
  [9:8] RTCSEL — RTC and TAMP kernel clock source enable and selection
    0=no clock selected, RTC and TAMP kernel clock disabled; 1=LSE oscillator clock selected, and enabled; 2=LSI oscillator clock selected, and enabled; 3=HSE32 oscillator clock divided by 32 selected, and enabled
  [7] LSESYSEN — LSE system clock (LSESYS) enable
    0=LSESYS clock disabled; 1=LSESYS clock enabled
  [6] LSECSSD ro — Low speed external clock security, LSE failure Detection
    0=no failure detected on LSE; 1=failure detected on LSE
  [5] LSECSSON — Low speed external clock security enable
    0=LSECSS disabled off; 1=LSECSS enabled on
  [4:3] LSEDRV — LSE oscillator drive capability
    1=Xtal mode' medium-low driving capability; 2=Xtal mode' medium-high driving capability; 3=Xtal mode' higher driving capability
  [2] LSEBYP — LSE oscillator bypass
    0=LSE oscillator Xtal' mode; 1=LSE oscillator bypassed
  [1] LSERDY ro — LSE oscillator ready
    0=LSE oscillator not ready; 1=LSE oscillator ready
  [0] LSEON — LSE oscillator enable
    0=LSE oscillator off; 1=LSE oscillator on
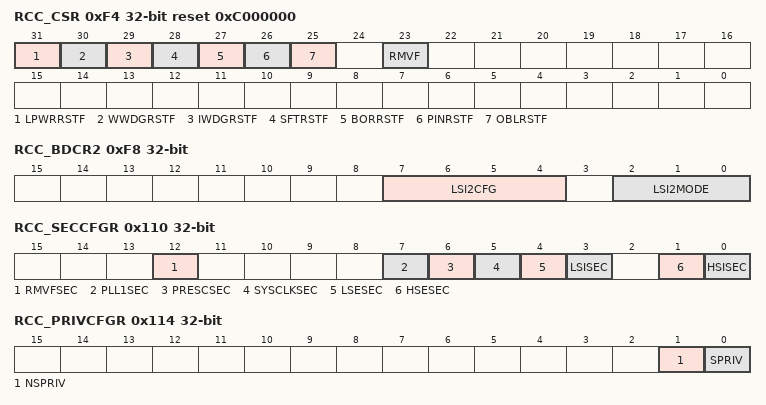
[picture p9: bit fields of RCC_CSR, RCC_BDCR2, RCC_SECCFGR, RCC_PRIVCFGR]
0xF4 RCC_CSR reset 0xC000000 — RCC control/status register
  [31] LPWRRSTF ro — Low-power reset flag
    0=no illegal mode reset occurred; 1=illegal mode reset occurred
  [30] WWDGRSTF ro — Window watchdog reset flag
    0=no window watchdog reset occurred; 1=window watchdog reset occurred
  [29] IWDGRSTF ro — Independent watchdog reset flag
    0=no independent watchdog reset occurred; 1=independent watchdog reset occurred
  [28] SFTRSTF ro — Software reset flag
    0=no software reset occurred; 1=software reset occurred
  [27] BORRSTF ro — BOR flag
    0=no BOR occurred; 1=BOR occurred
  [26] PINRSTF ro — NRST pin reset flag
    0=No reset from NRST pin occurred; 1=Reset from NRST pin occurred
  [25] OBLRSTF ro — Option byte loader reset flag
    0=No reset from option byte loading occurred; 1=Reset from option byte loading occurred
  [23] RMVF — Remove reset flag
    0=No effect; 1=Clear the reset flags (once set by software bit is cleared automatically by hardware)
0xF8 RCC_BDCR2 — RCC Backup domain control register
  [7:4] LSI2CFG — LSI2 oscillator configuration
    0=LSI2 frequency temperature sensitivity is close to 0 at +80 less thansup oless than/sup C; 1=LSI2 frequency temperature sensitivity is close to 0 at +50 less thansup oless than/sup C; 2=LSI2 frequency temperature sensitivity is close to 0 at +20 less thansup oless than/sup C
  [2:0] LSI2MODE — LSI2 oscillator operating mode configuration
    0=nominal-power, high accuracy; 1=low-power, medium accuracy; 2=ultra-low-power, low accuracy
0x110 RCC_SECCFGR — RCC secure configuration register
  [all] fields
    0=Non secure; 1=Secure
  [12] RMVFSEC — Remove reset flag security
  [7] PLL1SEC — PLL1 clock configuration and status bits security
  [6] PRESCSEC — AHBx/APBx prescaler configuration bits security
  [5] SYSCLKSEC — SYSCLK selection, clock output on MCO configuration security
  [4] LSESEC — LSE clock configuration and status bits security
  [3] LSISEC — LSI clock configuration and status bits security
  [1] HSESEC — HSE32 clock configuration bits, status bits and HSECSS security
  [0] HSISEC — HSI16 clock configuration and status bits security
0x114 RCC_PRIVCFGR — RCC privilege configuration register
  [1] NSPRIV — RCC non-secure functions privilege configuration
    0=Read and write to RCC non-secure functions can be done by privileged or unprivileged access; 1=Read and write to RCC non-secure functions can be done by privileged access only
  [0] SPRIV — RCC secure functions privilege configuration
    0=Read and write to RCC secure functions can be done by privileged or unprivileged access; 1=Read and write to RCC secure functions can be done by privileged access only
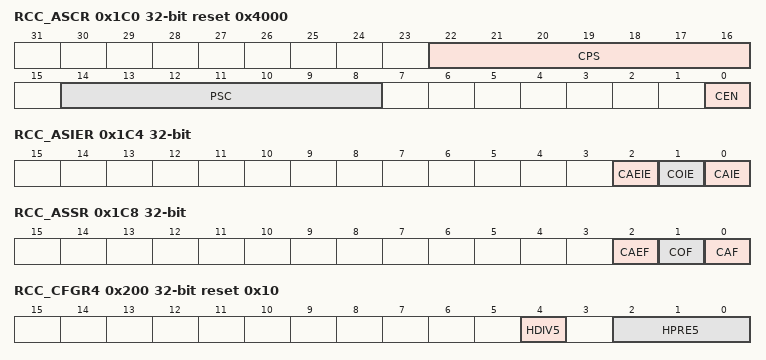
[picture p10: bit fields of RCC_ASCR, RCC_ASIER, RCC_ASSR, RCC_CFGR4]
0x1C0 RCC_ASCR reset 0x4000 — RCC audio synchronization control register
  [22:16] CPS — Capture prescaler
  [14:8] PSC — Clock prescaler
  [0] CEN — Counter enable
    0=Audio synchronization counter and kernel clock disabled; 1=Audio synchronization counter and kernel clock enabled
0x1C4 RCC_ASIER — RCC audio synchronization interrupt enable register
  [2] CAEIE — Capture error interrupt enable
    0=Capture error interrupt disabled and flag masked; 1=Capture error interrupt and flag enabled
  [1] COIE — Comparer interrupt enable
    0=Compare interrupt disabled and flag masked; 1=Compare interrupt and flag enabled
  [0] CAIE — Capture trigger interrupt enable
    0=Capture trigger interrupt disabled and flag masked; 1=Capture trigger interrupt and flag enabled
0x1C8 RCC_ASSR — RCC audio synchronization status register
  [2] CAEF — Capture error interrupt flag
    0=No capture error has been detected; 1=A capture error has been detected
  [1] COF — Comparer interrupt flag
    0=No counter compare occurred; 1=A counter compare has occurred
  [0] CAF — Capture trigger interrupt flag
    0=No capture update occurred; 1=A capture update has occurred
0x1CC RCC_ASCNTR ro — RCC audio synchronization counter register
  [19:0] CNT — Counter value
0x1D0 RCC_ASARR reset 0x80000 — RCC audio synchronization auto-reload register
  [19:0] AR — Auto-reload value
0x1D4 RCC_ASCAR ro — RCC audio synchronization capture register
  [26:0] CA — Capture value
0x1D8 RCC_ASCOR — RCC audio synchronization compare register
  [19:0] CO — Compare value
0x200 RCC_CFGR4 reset 0x10 — RCC clock configuration register 2
  [4] HDIV5 — AHB5 divider when SWS select HSI16 or HSE32
    0=hclk5 = SYSCLK not divided; 1=hclk5 = SYSCLK divided by 2
  [2:0] HPRE5 — AHB5 prescaler when SWS select PLL1
    4=hclk5 = SYSCLK divided by 2; 5=hclk5 = SYSCLK divided by 3; 6=hclk5 = SYSCLK divided by 4; 7=hclk5 = SYSCLK divided by 6
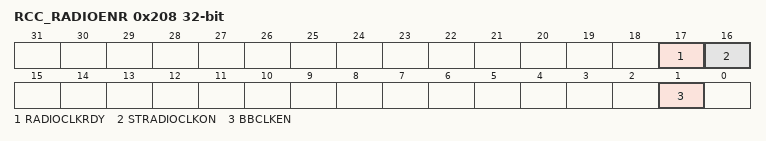
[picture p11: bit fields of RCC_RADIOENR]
0x208 RCC_RADIOENR — RCC RADIO peripheral clock enable register
  [all] fields
    0=2; 1=2
  [17] RADIOCLKRDY ro — 2.
  [16] STRADIOCLKON — 2.
  [1] BBCLKEN — 2.
0x210 RCC_ECSCR1 reset 0x200000 — RCC external clock sources calibration register 1
  [21:16] HSETRIM — HSE32 clock trimming
